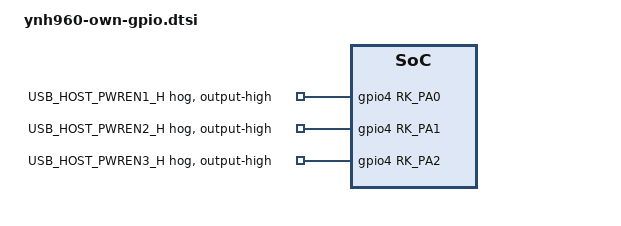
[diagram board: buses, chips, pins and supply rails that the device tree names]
// ynh960: retire gpio_innohi / own-gpio hog; free product pads for userspace gpiod.
//
// Product RGB (GPIO_4/5/7), BELL, GPIO_1…3/6/8, LED_RED/BLUE stay unclaimed so
// flutter_gpiod can request chip+offset (see app gpio.json). Silk WG_D0/D1 =
// GPIO_7 (green) / GPIO_8 (spare) — no Wiegand chardev.
//
// USB_HOST_PWREN* remain kernel-owned via gpio-hog (output-high) so 1 mm host
// VBUS does not depend on /sys/class/gpio_innohi. Under EVB RGMII those pads
// conflicted with gmac1; product RMII frees gpio4 PA0/PA1/PA2.

&own_gpio {
	status = "disabled";
};

&own_boot_gpio {
	status = "disabled";
};

&gpio4 {
	usb_host_pwren1_hog {
		gpio-hog;
		gpios = <RK_PA0 GPIO_ACTIVE_HIGH>;
		output-high;
		line-name = "USB_HOST_PWREN1_H";
	};

	usb_host_pwren2_hog {
		gpio-hog;
		gpios = <RK_PA1 GPIO_ACTIVE_HIGH>;
		output-high;
		line-name = "USB_HOST_PWREN2_H";
	};

	usb_host_pwren3_hog {
		gpio-hog;
		gpios = <RK_PA2 GPIO_ACTIVE_HIGH>;
		output-high;
		line-name = "USB_HOST_PWREN3_H";
	};
};
